VERSION ""

NS_ :

BS_:

BU_: AS Other

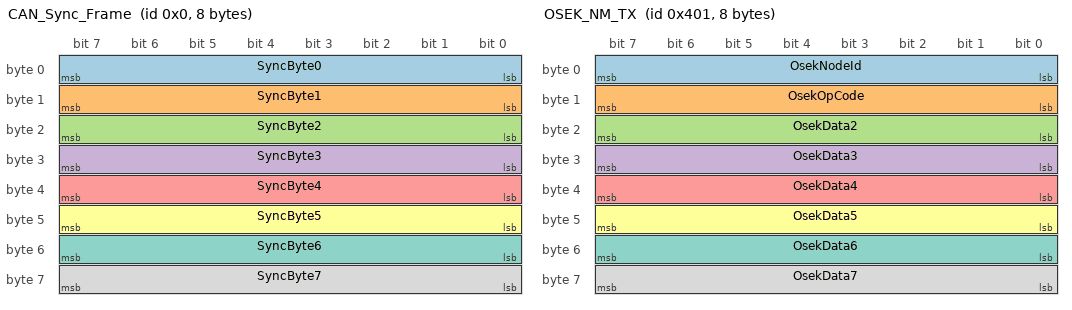
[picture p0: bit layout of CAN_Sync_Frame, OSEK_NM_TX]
BO_ 0 CAN_Sync_Frame: 8 AS
 SG_ SyncByte0 : 0|8@1+ (1,0) [0|255] "" Other
 SG_ SyncByte1 : 8|8@1+ (1,0) [0|255] "" Other
 SG_ SyncByte2 : 16|8@1+ (1,0) [0|255] "" Other
 SG_ SyncByte3 : 24|8@1+ (1,0) [0|255] "" Other
 SG_ SyncByte4 : 32|8@1+ (1,0) [0|255] "" Other
 SG_ SyncByte5 : 40|8@1+ (1,0) [0|255] "" Other
 SG_ SyncByte6 : 48|8@1+ (1,0) [0|255] "" Other
 SG_ SyncByte7 : 56|8@1+ (1,0) [0|255] "" Other

BO_ 1025 OSEK_NM_TX: 8 AS
 SG_ OsekNodeId : 0|8@1+ (1,0) [0|255] "" Other
 SG_ OsekOpCode : 8|8@1+ (1,0) [0|255] "" Other
 SG_ OsekData2 : 16|8@1+ (1,0) [0|255] "" Other
 SG_ OsekData3 : 24|8@1+ (1,0) [0|255] "" Other
 SG_ OsekData4 : 32|8@1+ (1,0) [0|255] "" Other
 SG_ OsekData5 : 40|8@1+ (1,0) [0|255] "" Other
 SG_ OsekData6 : 48|8@1+ (1,0) [0|255] "" Other
 SG_ OsekData7 : 56|8@1+ (1,0) [0|255] "" Other

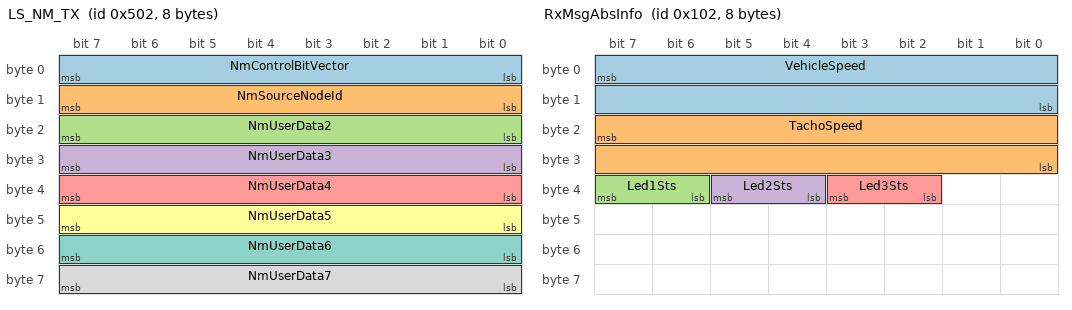
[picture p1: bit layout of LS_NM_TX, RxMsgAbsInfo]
BO_ 1282 LS_NM_TX: 8 AS
 SG_ NmControlBitVector : 0|8@1+ (1,0) [0|255] "" Other
 SG_ NmSourceNodeId : 8|8@1+ (1,0) [0|255] "" Other
 SG_ NmUserData2 : 16|8@1+ (1,0) [0|255] "" Other
 SG_ NmUserData3 : 24|8@1+ (1,0) [0|255] "" Other
 SG_ NmUserData4 : 32|8@1+ (1,0) [0|255] "" Other
 SG_ NmUserData5 : 40|8@1+ (1,0) [0|255] "" Other
 SG_ NmUserData6 : 48|8@1+ (1,0) [0|255] "" Other
 SG_ NmUserData7 : 56|8@1+ (1,0) [0|255] "" Other

BO_ 258 RxMsgAbsInfo: 8 Other
 SG_ VehicleSpeed : 7|16@0+ (0.1,0) [0|300] "km/h" AS
 SG_ TachoSpeed : 23|16@0+ (1,0) [0|8000] "rpm" AS
 SG_ Led1Sts : 39|2@0+ (1,0) [0|3] "" AS
 SG_ Led2Sts : 37|2@0+ (1,0) [0|3] "" AS
 SG_ Led3Sts : 35|2@0+ (1,0) [0|3] "" AS

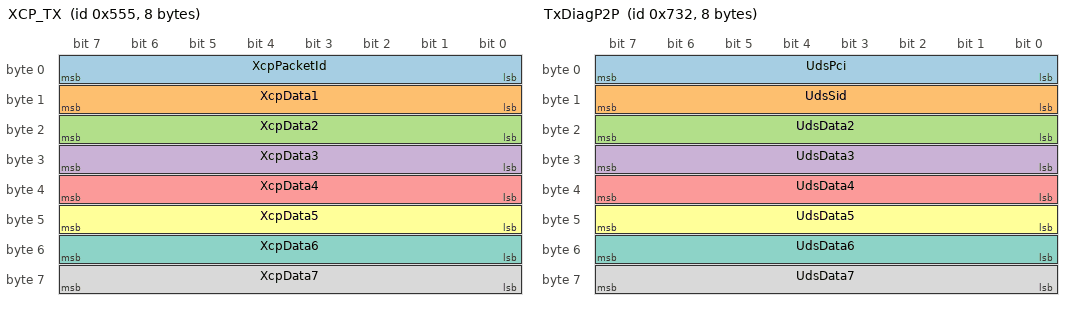
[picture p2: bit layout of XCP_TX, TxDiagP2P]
BO_ 1365 XCP_TX: 8 AS
 SG_ XcpPacketId : 0|8@1+ (1,0) [0|255] "" Other
 SG_ XcpData1 : 8|8@1+ (1,0) [0|255] "" Other
 SG_ XcpData2 : 16|8@1+ (1,0) [0|255] "" Other
 SG_ XcpData3 : 24|8@1+ (1,0) [0|255] "" Other
 SG_ XcpData4 : 32|8@1+ (1,0) [0|255] "" Other
 SG_ XcpData5 : 40|8@1+ (1,0) [0|255] "" Other
 SG_ XcpData6 : 48|8@1+ (1,0) [0|255] "" Other
 SG_ XcpData7 : 56|8@1+ (1,0) [0|255] "" Other

BO_ 1842 TxDiagP2P: 8 AS
 SG_ UdsPci : 0|8@1+ (1,0) [0|255] "" Other
 SG_ UdsSid : 8|8@1+ (1,0) [0|255] "" Other
 SG_ UdsData2 : 16|8@1+ (1,0) [0|255] "" Other
 SG_ UdsData3 : 24|8@1+ (1,0) [0|255] "" Other
 SG_ UdsData4 : 32|8@1+ (1,0) [0|255] "" Other
 SG_ UdsData5 : 40|8@1+ (1,0) [0|255] "" Other
 SG_ UdsData6 : 48|8@1+ (1,0) [0|255] "" Other
 SG_ UdsData7 : 56|8@1+ (1,0) [0|255] "" Other

VAL_ 258 Led1Sts 0 "OFF" 1 "ON" 2 "BLINK_1HZ" 3 "BLINK_2HZ" ;
VAL_ 258 Led2Sts 0 "OFF" 1 "ON" 2 "BLINK_1HZ" 3 "BLINK_2HZ" ;
VAL_ 258 Led3Sts 0 "OFF" 1 "ON" 2 "BLINK_1HZ" 3 "BLINK_2HZ" ;
VAL_ 1025 OsekOpCode 1 "RING" 2 "ALIVE" 3 "LIMPHOME" ;

BA_DEF_ BO_ "GenMsgCycleTime" INT 0 65535;
BA_ "GenMsgCycleTime" BO_ 0 100;
BA_ "GenMsgCycleTime" BO_ 258 100;
BA_ "GenMsgCycleTime" BO_ 1025 100;
BA_ "GenMsgCycleTime" BO_ 1282 100;
